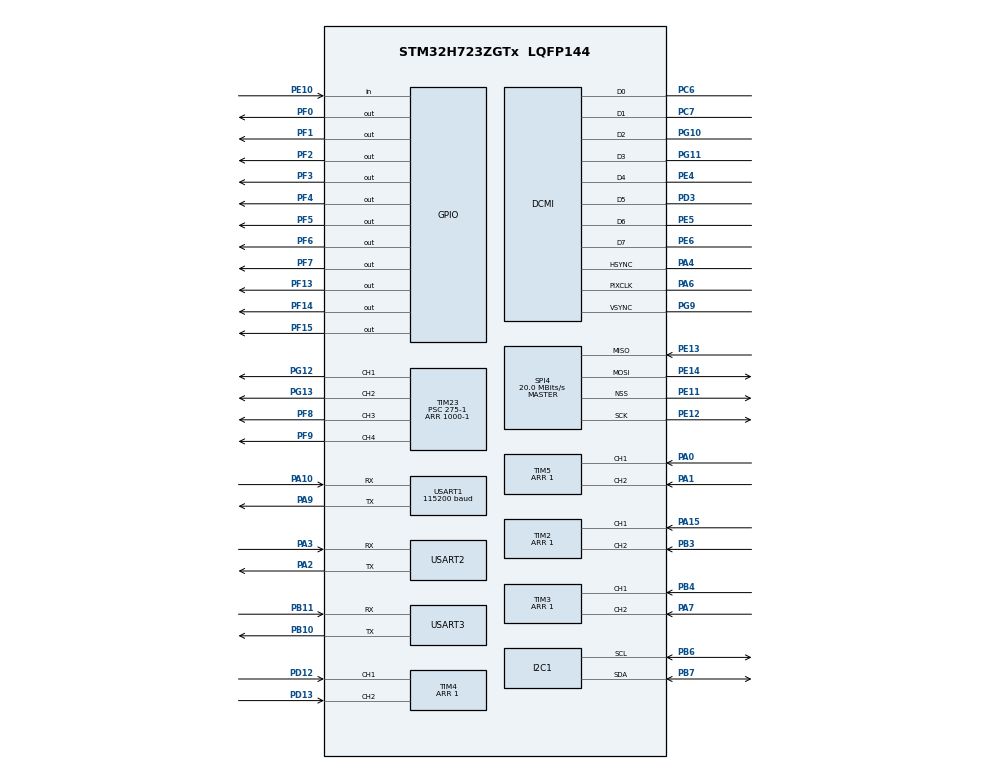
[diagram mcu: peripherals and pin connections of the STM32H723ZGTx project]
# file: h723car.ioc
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CORTEX_M7.AccessPermission_Spec=MPU_REGION_FULL_ACCESS
CORTEX_M7.BaseAddress_Spec=0x24000000
CORTEX_M7.CPU_DCache=Enabled
CORTEX_M7.CPU_ICache=Enabled
CORTEX_M7.DisableExec_Spec=MPU_INSTRUCTION_ACCESS_ENABLE
CORTEX_M7.IsBufferable_Spec=MPU_ACCESS_BUFFERABLE
CORTEX_M7.IsCacheable_Spec=MPU_ACCESS_CACHEABLE
CORTEX_M7.IsShareable_Spec=MPU_ACCESS_SHAREABLE
CORTEX_M7.Size_Spec=MPU_REGION_SIZE_512KB
CORTEX_M7.SubRegionDisable_Spec=0x00
CORTEX_M7.default_mode_Activation=1
DCMI.JPEGMode=DCMI_JPEG_ENABLE
DCMI.PCKPolarity=DCMI_PCKPOLARITY_RISING
Dma.DCMI.2.Direction=DMA_PERIPH_TO_MEMORY
Dma.DCMI.2.EventEnable=DISABLE
Dma.DCMI.2.FIFOMode=DMA_FIFOMODE_ENABLE
Dma.DCMI.2.FIFOThreshold=DMA_FIFO_THRESHOLD_FULL
Dma.DCMI.2.Instance=DMA1_Stream2
Dma.DCMI.2.MemBurst=DMA_MBURST_SINGLE
Dma.DCMI.2.MemDataAlignment=DMA_MDATAALIGN_WORD
Dma.DCMI.2.MemInc=DMA_MINC_ENABLE
Dma.DCMI.2.Mode=DMA_NORMAL
Dma.DCMI.2.PeriphBurst=DMA_PBURST_SINGLE
Dma.DCMI.2.PeriphDataAlignment=DMA_PDATAALIGN_WORD
Dma.DCMI.2.PeriphInc=DMA_PINC_DISABLE
Dma.DCMI.2.Polarity=HAL_DMAMUX_REQ_GEN_RISING
Dma.DCMI.2.Priority=DMA_PRIORITY_VERY_HIGH
Dma.DCMI.2.RequestNumber=1
Dma.DCMI.2.SignalID=NONE
Dma.DCMI.2.SyncEnable=DISABLE
Dma.DCMI.2.SyncPolarity=HAL_DMAMUX_SYNC_NO_EVENT
Dma.DCMI.2.SyncRequestNumber=1
Dma.DCMI.2.SyncSignalID=NONE
Dma.Request0=USART1_RX
Dma.Request1=USART3_RX
Dma.Request2=DCMI
Dma.Request3=USART2_RX
Dma.USART1_RX.0.Direction=DMA_PERIPH_TO_MEMORY
Dma.USART1_RX.0.EventEnable=DISABLE
Dma.USART1_RX.0.FIFOMode=DMA_FIFOMODE_DISABLE
Dma.USART1_RX.0.Instance=DMA1_Stream0
Dma.USART1_RX.0.MemDataAlignment=DMA_MDATAALIGN_BYTE
Dma.USART1_RX.0.MemInc=DMA_MINC_ENABLE
Dma.USART1_RX.0.Mode=DMA_NORMAL
Dma.USART1_RX.0.PeriphDataAlignment=DMA_PDATAALIGN_BYTE
Dma.USART1_RX.0.PeriphInc=DMA_PINC_DISABLE
Dma.USART1_RX.0.Polarity=HAL_DMAMUX_REQ_GEN_RISING
Dma.USART1_RX.0.Priority=DMA_PRIORITY_LOW
Dma.USART1_RX.0.RequestNumber=1
Dma.USART1_RX.0.SignalID=NONE
Dma.USART1_RX.0.SyncEnable=DISABLE
Dma.USART1_RX.0.SyncPolarity=HAL_DMAMUX_SYNC_NO_EVENT
Dma.USART1_RX.0.SyncRequestNumber=1
Dma.USART1_RX.0.SyncSignalID=NONE
Dma.USART2_RX.3.Direction=DMA_PERIPH_TO_MEMORY
Dma.USART2_RX.3.EventEnable=DISABLE
Dma.USART2_RX.3.FIFOMode=DMA_FIFOMODE_DISABLE
Dma.USART2_RX.3.Instance=DMA1_Stream1
Dma.USART2_RX.3.MemDataAlignment=DMA_MDATAALIGN_BYTE
Dma.USART2_RX.3.MemInc=DMA_MINC_ENABLE
Dma.USART2_RX.3.Mode=DMA_NORMAL
Dma.USART2_RX.3.PeriphDataAlignment=DMA_PDATAALIGN_BYTE
Dma.USART2_RX.3.PeriphInc=DMA_PINC_DISABLE
Dma.USART2_RX.3.Polarity=HAL_DMAMUX_REQ_GEN_RISING
Dma.USART2_RX.3.Priority=DMA_PRIORITY_LOW
Dma.USART2_RX.3.RequestNumber=1
Dma.USART2_RX.3.SignalID=NONE
Dma.USART2_RX.3.SyncEnable=DISABLE
Dma.USART2_RX.3.SyncPolarity=HAL_DMAMUX_SYNC_NO_EVENT
Dma.USART2_RX.3.SyncRequestNumber=1
Dma.USART2_RX.3.SyncSignalID=NONE
Dma.USART3_RX.1.Direction=DMA_PERIPH_TO_MEMORY
Dma.USART3_RX.1.EventEnable=DISABLE
Dma.USART3_RX.1.FIFOMode=DMA_FIFOMODE_DISABLE
Dma.USART3_RX.1.Instance=DMA1_Stream3
Dma.USART3_RX.1.MemDataAlignment=DMA_MDATAALIGN_BYTE
Dma.USART3_RX.1.MemInc=DMA_MINC_ENABLE
Dma.USART3_RX.1.Mode=DMA_NORMAL
Dma.USART3_RX.1.PeriphDataAlignment=DMA_PDATAALIGN_BYTE
Dma.USART3_RX.1.PeriphInc=DMA_PINC_DISABLE
Dma.USART3_RX.1.Polarity=HAL_DMAMUX_REQ_GEN_RISING
Dma.USART3_RX.1.Priority=DMA_PRIORITY_LOW
Dma.USART3_RX.1.RequestNumber=1
Dma.USART3_RX.1.SignalID=NONE
Dma.USART3_RX.1.SyncEnable=DISABLE
Dma.USART3_RX.1.SyncPolarity=HAL_DMAMUX_SYNC_NO_EVENT
Dma.USART3_RX.1.SyncRequestNumber=1
Dma.USART3_RX.1.SyncSignalID=NONE
FREERTOS.BinarySemaphores01=cam_frame_semaphore,Dynamic,NULL,Depleted
FREERTOS.Tasks01=defaultTask,8,128,StartDefaultTask,Default,NULL,Dynamic,NULL,NULL;camTask,40,2048,cam_task,Default,NULL,Dynamic,NULL,NULL;uartTask,40,256,uart_task,Default,NULL,Dynamic,NULL,NULL;motorTask,24,512,motor_task,Default,NULL,Dynamic,NULL,NULL;aht20Task,24,256,aht20_task,Default,NULL,Dynamic,NULL,NULL
FREERTOS.configLIBRARY_MAX_SYSCALL_INTERRUPT_PRIORITY=5
I2C1.Timing=0x60404E72
Mcu.Family=STM32H7
Mcu.Name=STM32H723ZGTx
Mcu.Package=LQFP144
NVIC.DCMI_PSSI_IRQn=true\:6\:0\:true\:false\:true\:true\:true\:true\:true
NVIC.DMA1_Stream0_IRQn=true\:5\:0\:false\:false\:true\:true\:false\:true\:true
NVIC.DMA1_Stream1_IRQn=true\:5\:0\:false\:false\:true\:true\:false\:true\:true
NVIC.DMA1_Stream2_IRQn=true\:5\:0\:false\:false\:true\:true\:false\:true\:true
NVIC.DMA1_Stream3_IRQn=true\:5\:0\:false\:false\:true\:true\:false\:true\:true
NVIC.PriorityGroup=NVIC_PRIORITYGROUP_4
NVIC.TIM17_IRQn=true\:15\:0\:false\:false\:true\:false\:false\:true\:true
NVIC.TIM2_IRQn=true\:5\:0\:false\:false\:true\:true\:true\:true\:true
NVIC.TIM3_IRQn=true\:5\:0\:false\:false\:true\:true\:true\:true\:true
NVIC.TIM4_IRQn=true\:5\:0\:false\:false\:true\:true\:true\:true\:true
NVIC.TIM5_IRQn=true\:5\:0\:false\:false\:true\:true\:true\:true\:true
NVIC.TimeBase=TIM17_IRQn
NVIC.TimeBaseIP=TIM17
NVIC.USART1_IRQn=true\:8\:0\:true\:false\:true\:true\:true\:true\:true
NVIC.USART2_IRQn=true\:8\:0\:true\:false\:true\:true\:true\:true\:true
NVIC.USART3_IRQn=true\:8\:0\:true\:false\:true\:true\:true\:true\:true
PA0.GPIO_Speed=GPIO_SPEED_FREQ_MEDIUM
PA0.Signal=S_TIM5_CH1
PA1.GPIO_Speed=GPIO_SPEED_FREQ_MEDIUM
PA1.Signal=S_TIM5_CH2
PA10.GPIO_Speed=GPIO_SPEED_FREQ_HIGH
PA10.Mode=Asynchronous
PA10.Signal=USART1_RX
PA13(JTMS/SWDIO).Mode=Serial_Wire
PA13(JTMS/SWDIO).Signal=DEBUG_JTMS-SWDIO
PA14(JTCK/SWCLK).Mode=Serial_Wire
PA14(JTCK/SWCLK).Signal=DEBUG_JTCK-SWCLK
PA15(JTDI).GPIO_Speed=GPIO_SPEED_FREQ_MEDIUM
PA15(JTDI).Signal=S_TIM2_CH1_ETR
PA2.Mode=Asynchronous
PA2.Signal=USART2_TX
PA3.Mode=Asynchronous
PA3.Signal=USART2_RX
PA4.GPIO_Speed=GPIO_SPEED_FREQ_VERY_HIGH
PA4.Mode=Slave_8_bits_External_Synchro
PA4.Signal=DCMI_HSYNC
PA6.GPIO_Speed=GPIO_SPEED_FREQ_VERY_HIGH
PA6.Mode=Slave_8_bits_External_Synchro
PA6.Signal=DCMI_PIXCLK
PA7.GPIO_Speed=GPIO_SPEED_FREQ_MEDIUM
PA7.Signal=S_TIM3_CH2
PA9.GPIO_Speed=GPIO_SPEED_FREQ_HIGH
PA9.Mode=Asynchronous
PA9.Signal=USART1_TX
PB10.Mode=Asynchronous
PB10.Signal=USART3_TX
PB11.Mode=Asynchronous
PB11.Signal=USART3_RX
PB3(JTDO/TRACESWO).GPIO_Speed=GPIO_SPEED_FREQ_MEDIUM
PB3(JTDO/TRACESWO).Signal=S_TIM2_CH2
PB4(NJTRST).GPIO_Speed=GPIO_SPEED_FREQ_MEDIUM
PB4(NJTRST).Signal=S_TIM3_CH1
PB6.GPIO_Pu=GPIO_PULLUP
PB6.Mode=I2C
PB6.Signal=I2C1_SCL
PB7.GPIO_Pu=GPIO_PULLUP
PB7.GPIO_Speed=GPIO_SPEED_FREQ_LOW
PB7.Mode=I2C
PB7.Signal=I2C1_SDA
PC6.GPIO_Speed=GPIO_SPEED_FREQ_VERY_HIGH
PC6.Mode=Slave_8_bits_External_Synchro
PC6.Signal=DCMI_D0
PC7.GPIO_Speed=GPIO_SPEED_FREQ_VERY_HIGH
PC7.Mode=Slave_8_bits_External_Synchro
PC7.Signal=DCMI_D1
PD12.GPIO_Speed=GPIO_SPEED_FREQ_MEDIUM
PD12.Signal=S_TIM4_CH1
PD13.GPIO_Speed=GPIO_SPEED_FREQ_MEDIUM
PD13.Signal=S_TIM4_CH2
PD3.GPIO_Speed=GPIO_SPEED_FREQ_VERY_HIGH
PD3.Mode=Slave_8_bits_External_Synchro
PD3.Signal=DCMI_D5
PE10.GPIO_Mode=GPIO_MODE_INPUT
PE10.GPIO_PuPd=GPIO_PULLUP
PE10.Signal=GPIO_Input
PE11.GPIO_PuPd=GPIO_PULLUP
PE11.GPIO_Speed=GPIO_SPEED_FREQ_MEDIUM
PE11.Mode=NSS_Signal_Hard_Output
PE11.Signal=SPI4_NSS
PE12.GPIO_Speed=GPIO_SPEED_FREQ_HIGH
PE12.Mode=Full_Duplex_Master
PE12.Signal=SPI4_SCK
PE13.GPIO_Speed=GPIO_SPEED_FREQ_HIGH
PE13.Mode=Full_Duplex_Master
PE13.Signal=SPI4_MISO
PE14.GPIO_Speed=GPIO_SPEED_FREQ_HIGH
PE14.Mode=Full_Duplex_Master
PE14.Signal=SPI4_MOSI
PE4.GPIO_Speed=GPIO_SPEED_FREQ_VERY_HIGH
PE4.Mode=Slave_8_bits_External_Synchro
PE4.Signal=DCMI_D4
PE5.GPIO_Speed=GPIO_SPEED_FREQ_VERY_HIGH
PE5.Mode=Slave_8_bits_External_Synchro
PE5.Signal=DCMI_D6
PE6.GPIO_Speed=GPIO_SPEED_FREQ_VERY_HIGH
PE6.Mode=Slave_8_bits_External_Synchro
PE6.Signal=DCMI_D7
PF0.GPIO_ModeDefaultOutputPP=GPIO_MODE_OUTPUT_PP
PF0.Signal=GPIO_Output
PF1.GPIO_ModeDefaultOutputPP=GPIO_MODE_OUTPUT_PP
PF1.Signal=GPIO_Output
PF13.GPIO_ModeDefaultOutputPP=GPIO_MODE_OUTPUT_PP
PF13.PinState=GPIO_PIN_RESET
PF13.Signal=GPIO_Output
PF14.GPIO_ModeDefaultOutputPP=GPIO_MODE_OUTPUT_PP
PF14.GPIO_PuPd=GPIO_NOPULL
PF14.GPIO_Speed=GPIO_SPEED_FREQ_HIGH
PF14.PinState=GPIO_PIN_SET
PF14.Signal=GPIO_Output
PF15.GPIO_ModeDefaultOutputPP=GPIO_MODE_OUTPUT_OD
PF15.GPIO_PuPd=GPIO_PULLUP
PF15.GPIO_Speed=GPIO_SPEED_FREQ_HIGH
PF15.PinState=GPIO_PIN_SET
PF15.Signal=GPIO_Output
PF2.GPIO_ModeDefaultOutputPP=GPIO_MODE_OUTPUT_PP
PF2.Signal=GPIO_Output
PF3.GPIO_ModeDefaultOutputPP=GPIO_MODE_OUTPUT_PP
PF3.Signal=GPIO_Output
PF4.GPIO_ModeDefaultOutputPP=GPIO_MODE_OUTPUT_PP
PF4.Signal=GPIO_Output
PF5.GPIO_ModeDefaultOutputPP=GPIO_MODE_OUTPUT_PP
PF5.Signal=GPIO_Output
PF6.GPIO_ModeDefaultOutputPP=GPIO_MODE_OUTPUT_PP
PF6.Signal=GPIO_Output
PF7.GPIO_ModeDefaultOutputPP=GPIO_MODE_OUTPUT_PP
PF7.Signal=GPIO_Output
PF8.GPIO_Speed=GPIO_SPEED_FREQ_MEDIUM
PF8.Signal=S_TIM23_CH3
PF9.GPIO_Speed=GPIO_SPEED_FREQ_MEDIUM
PF9.Signal=S_TIM23_CH4
PG10.GPIO_Speed=GPIO_SPEED_FREQ_VERY_HIGH
PG10.Mode=Slave_8_bits_External_Synchro
PG10.Signal=DCMI_D2
PG11.GPIO_Speed=GPIO_SPEED_FREQ_VERY_HIGH
PG11.Mode=Slave_8_bits_External_Synchro
PG11.Signal=DCMI_D3
PG12.GPIO_Speed=GPIO_SPEED_FREQ_MEDIUM
PG12.Mode=PWM Generation1 CH1
PG12.Signal=TIM23_CH1
PG13.GPIO_Speed=GPIO_SPEED_FREQ_MEDIUM
PG13.Signal=S_TIM23_CH2
PG9.GPIO_Speed=GPIO_SPEED_FREQ_VERY_HIGH
PG9.Mode=Slave_8_bits_External_Synchro
PG9.Signal=DCMI_VSYNC
PH0-OSC_IN.Mode=HSE-External-Oscillator
PH0-OSC_IN.Signal=RCC_OSC_IN
PH1-OSC_OUT.Mode=HSE-External-Oscillator
PH1-OSC_OUT.Signal=RCC_OSC_OUT
ProjectManager.HeapSize=0x2000
ProjectManager.StackSize=0x4000
ProjectManager.TargetToolchain=MDK-ARM V5.32
RCC.ADCFreq_Value=160000000
RCC.APB1Freq_Value=137500000
RCC.APB2Freq_Value=137500000
RCC.APB3Freq_Value=137500000
RCC.APB4Freq_Value=137500000
RCC.CortexFreq_Value=550000000
RCC.D1PPRE=RCC_APB3_DIV2
RCC.D2PPRE1=RCC_APB1_DIV2
RCC.D2PPRE2=RCC_APB2_DIV2
RCC.D3PPRE=RCC_APB4_DIV2
RCC.DIVM1=4
RCC.DIVN1=34
RCC.DIVN2=160
RCC.DIVP1=1
RCC.HCLKFreq_Value=275000000
RCC.HPRE=RCC_HCLK_DIV2
RCC.PLL2FRACN=0
RCC.PLL3FRACN=0
RCC.PLLFRACN=3072
RCC.SPI123CLockSelection=RCC_SPI123CLKSOURCE_PLL2
RCC.SYSCLKFreq_VALUE=550000000
RCC.SYSCLKSource=RCC_SYSCLKSOURCE_PLLCLK
RCC.Spi45ClockSelection=RCC_SPI45CLKSOURCE_PLL2
RCC.USBFreq_Value=275000000
SH.S_TIM23_CH2.0=TIM23_CH2,PWM Generation2 CH2
SH.S_TIM23_CH3.0=TIM23_CH3,PWM Generation3 CH3
SH.S_TIM23_CH4.0=TIM23_CH4,PWM Generation4 CH4
SH.S_TIM2_CH1_ETR.0=TIM2_CH1,Encoder_Interface
SH.S_TIM2_CH2.0=TIM2_CH2,Encoder_Interface
SH.S_TIM3_CH1.0=TIM3_CH1,Encoder_Interface
SH.S_TIM3_CH2.0=TIM3_CH2,Encoder_Interface
SH.S_TIM4_CH1.0=TIM4_CH1,Encoder_Interface
SH.S_TIM4_CH2.0=TIM4_CH2,Encoder_Interface
SH.S_TIM5_CH1.0=TIM5_CH1,Encoder_Interface
SH.S_TIM5_CH2.0=TIM5_CH2,Encoder_Interface
SPI4.BaudRatePrescaler=SPI_BAUDRATEPRESCALER_8
SPI4.CalculateBaudRate=20.0 MBits/s
SPI4.DataSize=SPI_DATASIZE_8BIT
SPI4.Direction=SPI_DIRECTION_2LINES
SPI4.Mode=SPI_MODE_MASTER
SPI4.VirtualNSS=VM_NSSHARD
SPI4.VirtualType=VM_MASTER
TIM2.IC1Filter=10
TIM2.IC2Filter=10
TIM2.Period=1
TIM23.AutoReloadPreload=TIM_AUTORELOAD_PRELOAD_ENABLE
TIM23.Channel-PWM\ Generation1\ CH1=TIM_CHANNEL_1
TIM23.Channel-PWM\ Generation2\ CH2=TIM_CHANNEL_2
TIM23.Channel-PWM\ Generation3\ CH3=TIM_CHANNEL_3
TIM23.Channel-PWM\ Generation4\ CH4=TIM_CHANNEL_4
TIM23.OCFastMode_PWM-PWM\ Generation1\ CH1=TIM_OCFAST_ENABLE
TIM23.OCFastMode_PWM-PWM\ Generation2\ CH2=TIM_OCFAST_ENABLE
TIM23.OCFastMode_PWM-PWM\ Generation3\ CH3=TIM_OCFAST_ENABLE
TIM23.OCFastMode_PWM-PWM\ Generation4\ CH4=TIM_OCFAST_ENABLE
TIM23.Period=1000-1
TIM23.Prescaler=275-1
TIM3.IC1Filter=10
TIM3.IC2Filter=10
TIM3.Period=1
TIM4.IC1Filter=10
TIM4.IC2Filter=10
TIM4.Period=1
TIM5.IC1Filter=10
TIM5.IC2Filter=10
TIM5.Period=1
TIM6.AutoReloadPreload=TIM_AUTORELOAD_PRELOAD_ENABLE
TIM6.Prescaler=27500-1
TIM7.Prescaler=275-1
USART1.BaudRate=115200
USART1.VirtualMode-Asynchronous=VM_ASYNC
USART2.VirtualMode-Asynchronous=VM_ASYNC
USART3.VirtualMode-Asynchronous=VM_ASYNC
VP_FREERTOS_VS_CMSIS_V2.Mode=CMSIS_V2
VP_MEMORYMAP_VS_MEMORYMAP.Mode=CurAppReg
VP_SYS_VS_tim17.Mode=TIM17
VP_TIM23_VS_ClockSourceINT.Mode=Internal
VP_TIM6_VS_ClockSourceINT.Mode=Enable_Timer
VP_TIM7_VS_ClockSourceINT.Mode=Enable_Timer
board=custom

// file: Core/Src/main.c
/* USER CODE BEGIN Header */
/**
  ******************************************************************************
  * @file           : main.c
  * @brief          : Main program body
  ******************************************************************************
  * @attention
  *
  * Copyright (c) 2025 STMicroelectronics.
  * All rights reserved.
  *
  * This software is licensed under terms that can be found in the LICENSE file
  * in the root directory of this software component.
  * If no LICENSE file comes with this software, it is provided AS-IS.
  *
  ******************************************************************************
  */
/* USER CODE END Header */
#include "main.h"
#include "cmsis_os.h"
#include "dcmi.h"
#include "dma.h"
#include "i2c.h"
#include "memorymap.h"
#include "spi.h"
#include "tim.h"
#include "usart.h"
#include "gpio.h"

/* USER CODE BEGIN Includes */
#include "bsp_system.h"
/* USER CODE END Includes */

void SystemClock_Config(void);
static void MPU_Config(void);
void MX_FREERTOS_Init(void);

int main(void)
{

  /* MPU Configuration--------------------------------------------------------*/
  MPU_Config();

  /* Enable the CPU Cache */

  /* Enable I-Cache---------------------------------------------------------*/
  SCB_EnableICache();

  /* Enable D-Cache---------------------------------------------------------*/
  SCB_EnableDCache();

  /* MCU Configuration--------------------------------------------------------*/

  /* Reset of all peripherals, Initializes the Flash interface and the Systick. */
  HAL_Init();

  /* Configure the system clock */
  SystemClock_Config();

  /* Initialize all configured peripherals */
  MX_GPIO_Init();
  MX_DMA_Init();
  MX_DCMI_Init();
  MX_USART1_UART_Init();
  MX_TIM7_Init();
  MX_SPI4_Init();
  MX_USART3_UART_Init();
  MX_TIM2_Init();
  MX_TIM3_Init();
  MX_TIM4_Init();
  MX_TIM5_Init();
  MX_TIM23_Init();
  MX_TIM6_Init();
  MX_I2C1_Init();
  MX_USART2_UART_Init();
  /* USER CODE BEGIN 2 */
	bsp_init();
  /* USER CODE END 2 */

  /* Init scheduler */
  osKernelInitialize();

  /* Call init function for freertos objects (in cmsis_os2.c) */
  MX_FREERTOS_Init();

  /* Start scheduler */
  osKernelStart();

  /* We should never get here as control is now taken by the scheduler */

  /* Infinite loop */
  /* USER CODE BEGIN WHILE */
  while (1)
  {
	myusart_transmit(&huart1, "never run to here\n");
    /* USER CODE END WHILE */

  }
}

void SystemClock_Config(void)
{
  RCC_OscInitTypeDef RCC_OscInitStruct = {0};
  RCC_ClkInitTypeDef RCC_ClkInitStruct = {0};

  /** Supply configuration update enable
  */
  HAL_PWREx_ConfigSupply(PWR_LDO_SUPPLY);

  /** Configure the main internal regulator output voltage
  */
  __HAL_PWR_VOLTAGESCALING_CONFIG(PWR_REGULATOR_VOLTAGE_SCALE0);

  while(!__HAL_PWR_GET_FLAG(PWR_FLAG_VOSRDY)) {}

  /** Initializes the RCC Oscillators according to the specified parameters
  * in the RCC_OscInitTypeDef structure.
  */
  RCC_OscInitStruct.OscillatorType = RCC_OSCILLATORTYPE_HSI;
  RCC_OscInitStruct.HSIState = RCC_HSI_DIV1;
  RCC_OscInitStruct.HSICalibrationValue = 64;
  RCC_OscInitStruct.PLL.PLLState = RCC_PLL_ON;
  RCC_OscInitStruct.PLL.PLLSource = RCC_PLLSOURCE_HSI;
  RCC_OscInitStruct.PLL.PLLM = 4;
  RCC_OscInitStruct.PLL.PLLN = 34;
  RCC_OscInitStruct.PLL.PLLP = 1;
  RCC_OscInitStruct.PLL.PLLQ = 2;
  RCC_OscInitStruct.PLL.PLLR = 2;
  RCC_OscInitStruct.PLL.PLLRGE = RCC_PLL1VCIRANGE_3;
  RCC_OscInitStruct.PLL.PLLVCOSEL = RCC_PLL1VCOWIDE;
  RCC_OscInitStruct.PLL.PLLFRACN = 3072;
  if (HAL_RCC_OscConfig(&RCC_OscInitStruct) != HAL_OK)
  {
    Error_Handler();
  }

  /** Initializes the CPU, AHB and APB buses clocks
  */
  RCC_ClkInitStruct.ClockType = RCC_CLOCKTYPE_HCLK|RCC_CLOCKTYPE_SYSCLK
                              |RCC_CLOCKTYPE_PCLK1|RCC_CLOCKTYPE_PCLK2
                              |RCC_CLOCKTYPE_D3PCLK1|RCC_CLOCKTYPE_D1PCLK1;
  RCC_ClkInitStruct.SYSCLKSource = RCC_SYSCLKSOURCE_PLLCLK;
  RCC_ClkInitStruct.SYSCLKDivider = RCC_SYSCLK_DIV1;
  RCC_ClkInitStruct.AHBCLKDivider = RCC_HCLK_DIV2;
  RCC_ClkInitStruct.APB3CLKDivider = RCC_APB3_DIV2;
  RCC_ClkInitStruct.APB1CLKDivider = RCC_APB1_DIV2;
  RCC_ClkInitStruct.APB2CLKDivider = RCC_APB2_DIV2;
  RCC_ClkInitStruct.APB4CLKDivider = RCC_APB4_DIV2;

  if (HAL_RCC_ClockConfig(&RCC_ClkInitStruct, FLASH_LATENCY_3) != HAL_OK)
  {
    Error_Handler();
  }
}

 /* MPU Configuration */

void MPU_Config(void)
{
  MPU_Region_InitTypeDef MPU_InitStruct = {0};

  /* Disables the MPU */
  HAL_MPU_Disable();

  /** Initializes and configures the Region and the memory to be protected
  */
  MPU_InitStruct.Enable = MPU_REGION_ENABLE;
  MPU_InitStruct.Number = MPU_REGION_NUMBER0;
  MPU_InitStruct.BaseAddress = 0x24000000;
  MPU_InitStruct.Size = MPU_REGION_SIZE_512KB;
  MPU_InitStruct.SubRegionDisable = 0x00;
  MPU_InitStruct.TypeExtField = MPU_TEX_LEVEL0;
  MPU_InitStruct.AccessPermission = MPU_REGION_FULL_ACCESS;
  MPU_InitStruct.DisableExec = MPU_INSTRUCTION_ACCESS_ENABLE;
  MPU_InitStruct.IsShareable = MPU_ACCESS_SHAREABLE;
  MPU_InitStruct.IsCacheable = MPU_ACCESS_CACHEABLE;
  MPU_InitStruct.IsBufferable = MPU_ACCESS_BUFFERABLE;

  HAL_MPU_ConfigRegion(&MPU_InitStruct);
  /* Enables the MPU */
  HAL_MPU_Enable(MPU_PRIVILEGED_DEFAULT);

}

void HAL_TIM_PeriodElapsedCallback(TIM_HandleTypeDef *htim)
{
  if (htim->Instance == TIM17)
  {
    HAL_IncTick();
  }
}

void Error_Handler(void)
{
  __disable_irq();
  while (1)
  {
  }
}

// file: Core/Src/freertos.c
/* USER CODE BEGIN Header */
/**
  ******************************************************************************
  * File Name          : freertos.c
  * Description        : Code for freertos applications
  ******************************************************************************
  * @attention
  *
  * Copyright (c) 2025 STMicroelectronics.
  * All rights reserved.
  *
  * This software is licensed under terms that can be found in the LICENSE file
  * in the root directory of this software component.
  * If no LICENSE file comes with this software, it is provided AS-IS.
  *
  ******************************************************************************
  */
/* USER CODE END Header */

#include "FreeRTOS.h"
#include "task.h"
#include "main.h"
#include "cmsis_os.h"

/* USER CODE BEGIN Includes */
#include "bsp_system.h"
/* USER CODE END Includes */

/* Definitions for defaultTask */
osThreadId_t defaultTaskHandle;
const osThreadAttr_t defaultTask_attributes = {
  .name = "defaultTask",
  .stack_size = 128 * 4,
  .priority = (osPriority_t) osPriorityLow,
};
/* Definitions for camTask */
osThreadId_t camTaskHandle;
const osThreadAttr_t camTask_attributes = {
  .name = "camTask",
  .stack_size = 2048 * 4,
  .priority = (osPriority_t) osPriorityHigh,
};
/* Definitions for uartTask */
osThreadId_t uartTaskHandle;
const osThreadAttr_t uartTask_attributes = {
  .name = "uartTask",
  .stack_size = 256 * 4,
  .priority = (osPriority_t) osPriorityHigh,
};
/* Definitions for motorTask */
osThreadId_t motorTaskHandle;
const osThreadAttr_t motorTask_attributes = {
  .name = "motorTask",
  .stack_size = 512 * 4,
  .priority = (osPriority_t) osPriorityNormal,
};
/* Definitions for aht20Task */
osThreadId_t aht20TaskHandle;
const osThreadAttr_t aht20Task_attributes = {
  .name = "aht20Task",
  .stack_size = 256 * 4,
  .priority = (osPriority_t) osPriorityNormal,
};
/* Definitions for cam_frame_semaphore */
osSemaphoreId_t cam_frame_semaphoreHandle;
const osSemaphoreAttr_t cam_frame_semaphore_attributes = {
  .name = "cam_frame_semaphore"
};

void StartDefaultTask(void *argument);
void cam_task(void *argument);
void uart_task(void *argument);
void motor_task(void *argument);
void aht20_task(void *argument);

void MX_FREERTOS_Init(void); /* (MISRA C 2004 rule 8.1) */

void MX_FREERTOS_Init(void) {

  /* Create the semaphores(s) */
  /* creation of cam_frame_semaphore */
  cam_frame_semaphoreHandle = osSemaphoreNew(1, 0, &cam_frame_semaphore_attributes);

  /* Create the thread(s) */
  /* creation of defaultTask */
  defaultTaskHandle = osThreadNew(StartDefaultTask, NULL, &defaultTask_attributes);

  /* creation of camTask */
  camTaskHandle = osThreadNew(cam_task, NULL, &camTask_attributes);

  /* creation of uartTask */
  uartTaskHandle = osThreadNew(uart_task, NULL, &uartTask_attributes);

  /* creation of motorTask */
  motorTaskHandle = osThreadNew(motor_task, NULL, &motorTask_attributes);

  /* creation of aht20Task */
  aht20TaskHandle = osThreadNew(aht20_task, NULL, &aht20Task_attributes);

}

void StartDefaultTask(void *argument)
{
  for(;;)
  {
    osDelay(1);
  }
}

void cam_task(void *argument)
{
  /* USER CODE BEGIN cam_task */
	camera_JPEG_init();
  /* Infinite loop */
  for(;;)
  {
	JPEG_run();
  }
  /* USER CODE END cam_task */
}

void uart_task(void *argument)
{
  /* USER CODE BEGIN uart_task */
  /* Infinite loop */
  for(;;)
  {
	usart_proc();
	osDelay(10);
  }
  /* USER CODE END uart_task */
}

void motor_task(void *argument)
{
  /* USER CODE BEGIN motor_task */
  /* Infinite loop */
  for(;;)
  {
	motor_proc();
	osDelay(10);
  }
  /* USER CODE END motor_task */
}

void aht20_task(void *argument)
{
  /* USER CODE BEGIN aht20_task */
	AHT20_Init();
  /* Infinite loop */
  for(;;)
  {
	AHT20_Read();
    osDelay(300);
  }
  /* USER CODE END aht20_task */
}
